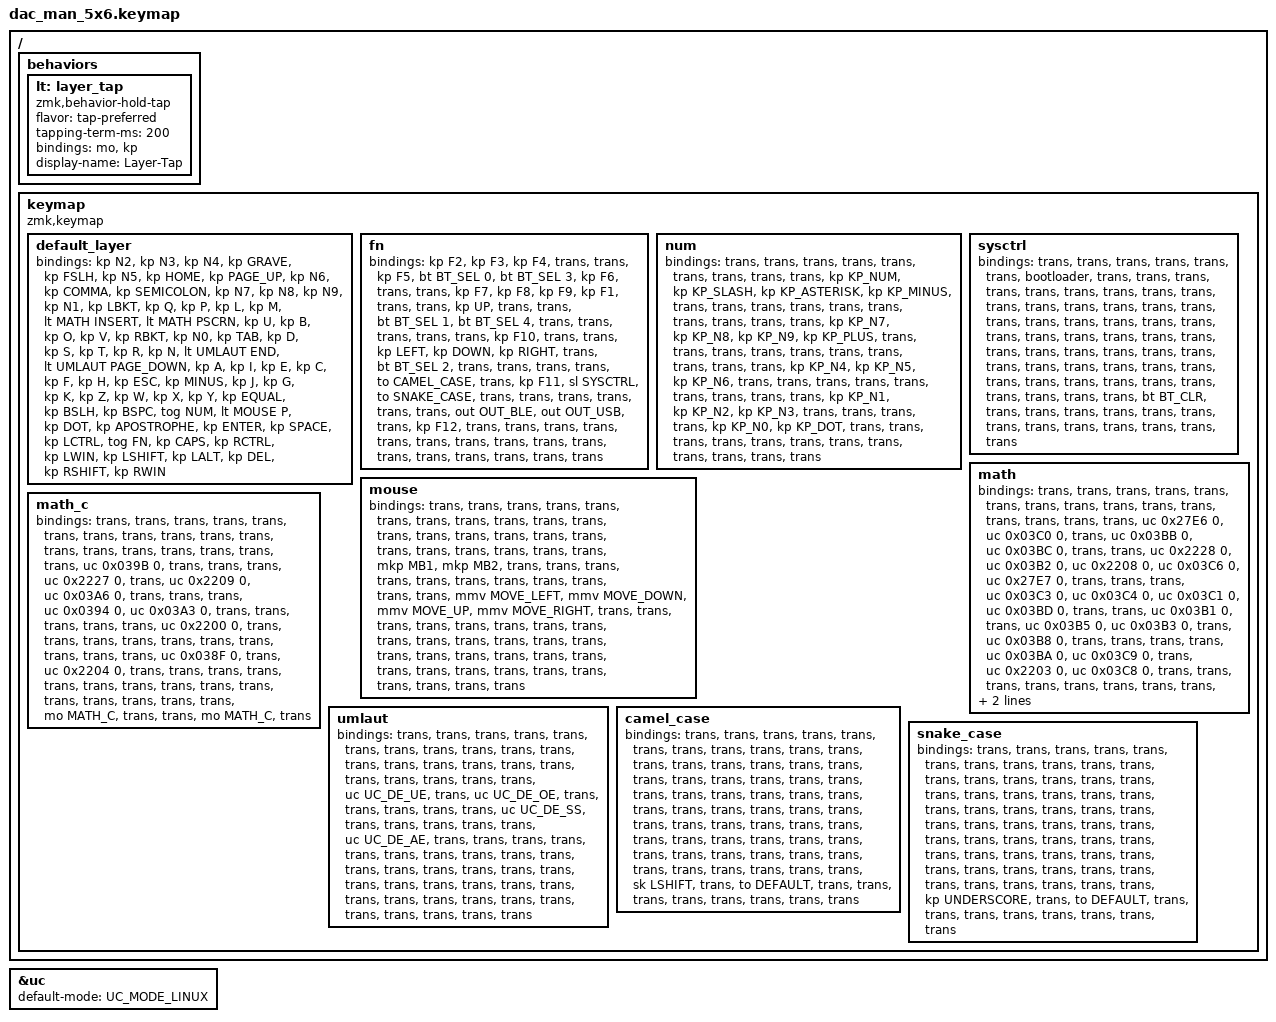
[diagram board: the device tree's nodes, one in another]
#include <behaviors.dtsi>
#include <dt-bindings/zmk/keys.h>
#include <dt-bindings/zmk/bt.h>
#include <dt-bindings/zmk/outputs.h>
#include <behaviors/unicode.dtsi>
#include <zmk-unicode/keys-extra.h>  // All glyphs except CJK
/* #include <zmk-unicode/keys-full.h>   // All glyphs including CJK */

// #define ZMK_POINTING_DEFAULT_MOVE_VAL 1500  // default: 600
// #define ZMK_POINTING_DEFAULT_SCRL_VAL 20    // default: 10

#include <dt-bindings/zmk/pointing.h>

#define DEFAULT     0
#define FN          1
#define NUM         2
#define SYSCTRL     3
#define MOUSE       4
#define MATH        5
#define MATH_C      6
#define UMLAUT      7
#define CAMEL_CASE  8
#define SNAKE_CASE  9

#define INDEX_RCTRL 63
#define INDEX_LSHIFT 65
#define INDEX_LALT 66

#define TAP_MS 10
#define WAIT_MS 10
#define TIMEOUT_MS 120

// QWERTY ///////////////

// #define INDEX_U 23
// #define INDEX_O 25
// #define INDEX_S 31
// #define INDEX_A 29

// QWERTY ///////////////

// // COLEMAK-DH ///////////
// #define INDEX_U 24
// #define INDEX_O 40
// #define INDEX_S 31
// #define INDEX_A 29
// // COLEMAK-DH ///////////

// carpalx: outputs-everythin_colemakstart //////////////////////////////////////////////////////////////////////////////////////////////////////////////////////////////////////////////////////////////////////////////////////////////////////////////
#define INDEX_BRACK_L 15
#define INDEX_Q 16
#define INDEX_P 17
#define INDEX_L 18
#define INDEX_M 19
#define INDEX_U 22
#define INDEX_B 23
#define INDEX_O 24
#define INDEX_V 25
#define INDEX_BRACK_R 26
#define INDEX_D 29
#define INDEX_S 30
#define INDEX_T 31
#define INDEX_R 32
#define INDEX_N 33
#define INDEX_A 36
#define INDEX_I 37
#define INDEX_E 38
#define INDEX_C 39
#define INDEX_F 40
#define INDEX_H 41
#define INDEX_J 44
#define INDEX_G 45
#define INDEX_K 46
#define INDEX_Z 47
#define INDEX_W 48
#define INDEX_X 49
#define INDEX_Y 50
// carpalx: outputs-everythin_colemakstart //////////////////////////////////////////////////////////////////////////////////////////////////////////////////////////////////////////////////////////////////////////////////////////////////////////////

&uc {
    default-mode = <UC_MODE_LINUX>;
};

/ {

    behaviors {
        lt: layer_tap {
            compatible = "zmk,behavior-hold-tap";
            #binding-cells = <2>;
            flavor = "tap-preferred";
            tapping-term-ms = <200>;
            bindings = <&mo>, <&kp>;
            display-name = "Layer-Tap";
        };
    };
    
    keymap {
        compatible = "zmk,keymap";

// // QWERTY //////////////////////////////////////////////////////////////////////////////////////////////////////////////////////////////////////////////////////////////////////////////////////////////////////////////////
//         default_layer {
//             bindings = <
// &kp GRAVE   &kp N2     &kp N3    &kp N4     &kp N5     &kp N6       &kp HOME                            &kp PSCRN       &kp N7     &kp N8     &kp N9     &kp N0     &kp MINUS      &kp EQUAL
// &kp N1      &kp Q      &kp W     &kp E      &kp R      &kp T        &kp INSERT                          &kp PAGE_UP     &kp Y      &kp U      &kp I      &kp O      &kp P          &kp BSLH
// &kp TAB     &kp A      &kp S     &kp D      &kp F      &kp G        &kp END                             &kp PAGE_DOWN   &kp H      &kp J      &kp K      &kp L      &kp SEMICOLON  &kp APOSTROPHE
// &kp ESC     &kp Z      &kp X     &kp C      &kp V      &kp B                                                            &kp N      &kp M      &kp COMMA  &kp DOT    &kp FSLH       &kp BSPC
//                        &tog NUM  &kp P                                                                                                        &kp LBKT   &kp RBKT
//                                             &kp ENTER    &kp SPACE   &kp LCTRL                          &tog FN &kp CAPS        &kp RCTRL
//                                             &kp LWIN     &kp LSHIFT  &kp LALT                           &kp DEL &kp RSHIFT      &kp RWIN
//             >;
//         };
// // QWERTY //////////////////////////////////////////////////////////////////////////////////////////////////////////////////////////////////////////////////////////////////////////////////////////////////////////////////

// // COLEMAK-DH //////////////////////////////////////////////////////////////////////////////////////////////////////////////////////////////////////////////////////////////////////////////////////////////////////////////
//         default_layer {
//             bindings = <
// &kp GRAVE   &kp N2     &kp N3    &kp N4     &kp N5     &kp N6       &kp HOME                            &kp PAGE_UP     &kp N7     &kp N8     &kp N9     &kp N0     &kp MINUS      &kp EQUAL
// &kp N1      &kp Q      &kp W     &kp F      &kp P      &kp B        &kp INSERT                          &kp PSCRN       &kp J      &kp L      &kp U      &kp Y      &kp SEMICOLON  &kp BSLH
// &kp TAB     &kp A      &kp R     &kp S      &kp T      &kp G        &kp END                             &kp PAGE_DOWN   &kp M      &kp N      &kp E      &kp I      &kp O          &kp APOSTROPHE
// &kp ESC     &kp Z      &kp X     &kp C      &kp D      &kp V                                                            &kp K      &kp H      &kp COMMA  &kp DOT    &kp FSLH       &kp BSPC
//                        &tog NUM  &kp P                                                                                                        &kp LBKT   &kp RBKT
//                                             &lt COLEMAK_ARROWS ENTER  &kp SPACE    &kp LCTRL                           &tog FN         &kp CAPS   &kp RCTRL
//                                             &kp LWIN   &kp LSHIFT   &kp LALT                            &kp DEL         &kp RSHIFT &kp RWIN
//             >;
//         };
// // COLEMAK-DH //////////////////////////////////////////////////////////////////////////////////////////////////////////////////////////////////////////////////////////////////////////////////////////////////////////////

// carpalx: outputs-everythin_colemakstart //////////////////////////////////////////////////////////////////////////////////////////////////////////////////////////////////////////////////////////////////////////////////////////////////////////////
        default_layer {
            bindings = <
&kp N2  &kp N3      &kp N4      &kp GRAVE   &kp FSLH    &kp N5      &kp HOME                                &kp PAGE_UP             &kp N6      &kp COMMA   &kp SEMICOLON   &kp N7      &kp N8      &kp N9
&kp N1  &kp LBKT    &kp Q       &kp P       &kp L       &kp M       &lt MATH INSERT                         &lt MATH PSCRN          &kp U       &kp B       &kp O           &kp V       &kp RBKT    &kp N0
&kp TAB &kp D       &kp S       &kp T       &kp R       &kp N       &lt UMLAUT END                          &lt UMLAUT PAGE_DOWN    &kp A       &kp I       &kp E           &kp C       &kp F       &kp H    
&kp ESC &kp MINUS   &kp J       &kp G       &kp K       &kp Z                                                                       &kp W       &kp X       &kp Y           &kp EQUAL   &kp BSLH    &kp BSPC
                    &tog NUM    &lt MOUSE P                                                                                                                 &kp DOT         &kp APOSTROPHE
                                            &kp ENTER   &kp SPACE   &kp LCTRL                               &tog FN                 &kp CAPS    &kp RCTRL
                                            &kp LWIN    &kp LSHIFT  &kp LALT                                &kp DEL                 &kp RSHIFT  &kp RWIN
            >;
        };
// carpalx: outputs-everythin_colemakstart //////////////////////////////////////////////////////////////////////////////////////////////////////////////////////////////////////////////////////////////////////////////////////////////////////////////

        fn{
            bindings = <
&kp F2          &kp F3          &kp F4      &trans          &trans      &kp F5  &bt BT_SEL 0                                    &bt BT_SEL 3  &kp F6    &trans    &trans          &kp F7         &kp F8  &kp F9
&kp F1          &trans          &trans      &kp UP          &trans      &trans  &bt BT_SEL 1                                    &bt BT_SEL 4  &trans    &trans    &trans          &trans         &trans  &kp F10
&trans          &trans          &kp LEFT    &kp DOWN        &kp RIGHT   &trans  &bt BT_SEL 2                                    &trans        &trans    &trans    &trans          &to CAMEL_CASE &trans  &kp F11
&sl SYSCTRL     &to SNAKE_CASE  &trans      &trans          &trans      &trans                                                                &trans    &trans    &out OUT_BLE    &out OUT_USB   &trans  &kp F12
                                &trans      &trans                                                                                                      &trans          &trans
                                                            &trans      &trans  &trans                                          &trans        &trans    &trans
                                                            &trans      &trans  &trans                                          &trans        &trans    &trans
            >;
        };

        num{
            bindings = <
&trans  &trans  &trans  &trans  &trans  &trans  &trans                      &trans  &trans  &kp KP_NUM  &kp KP_SLASH  &kp KP_ASTERISK    &kp KP_MINUS    &trans
&trans  &trans  &trans  &trans  &trans  &trans  &trans                      &trans  &trans  &kp KP_N7   &kp KP_N8     &kp KP_N9          &kp KP_PLUS     &trans
&trans  &trans  &trans  &trans  &trans  &trans  &trans                      &trans  &trans  &kp KP_N4   &kp KP_N5     &kp KP_N6          &trans          &trans
&trans  &trans  &trans  &trans  &trans  &trans                                      &trans  &kp KP_N1   &kp KP_N2     &kp KP_N3          &trans          &trans
        &trans  &trans                                                                                  &kp KP_N0     &kp KP_DOT
                                &trans  &trans  &trans                      &trans  &trans  &trans
                                &trans  &trans  &trans                      &trans  &trans  &trans
            >;
        };

        sysctrl{
            bindings = <
&trans  &trans  &trans  &trans  &trans  &trans  &bootloader                 &trans  &trans  &trans      &trans  &trans  &trans  &trans
&trans  &trans  &trans  &trans  &trans  &trans  &trans                      &trans  &trans  &trans      &trans  &trans  &trans  &trans
&trans  &trans  &trans  &trans  &trans  &trans  &trans                      &trans  &trans  &trans      &trans  &trans  &trans  &trans
&trans  &trans  &trans  &trans  &trans  &trans                                      &trans  &trans      &trans  &trans  &trans  &trans
                        &trans  &trans                                                      &bt BT_CLR  &trans
                                        &trans  &trans  &trans      &trans  &trans  &trans
                                        &trans  &trans  &trans      &trans  &trans  &trans
            >;
        };

        mouse{
            bindings = <
&trans  &trans  &trans  &trans  &trans  &trans  &trans       &trans  &trans         &trans          &trans          &trans          &trans  &trans
&trans  &trans  &trans  &trans  &trans  &trans  &trans       &trans  &trans         &mkp MB1        &mkp MB2        &trans          &trans  &trans
&trans  &trans  &trans  &trans  &trans  &trans  &trans       &trans  &mmv MOVE_LEFT &mmv MOVE_DOWN  &mmv MOVE_UP    &mmv MOVE_RIGHT &trans  &trans
&trans  &trans  &trans  &trans  &trans  &trans                       &trans         &trans          &trans          &trans          &trans  &trans
                &trans  &trans                                                                      &trans          &trans
                                &trans  &trans  &trans       &trans  &trans         &trans
                                &trans  &trans  &trans       &trans  &trans         &trans
            >;
        };


        math{
            bindings = <
&trans  &trans          &trans          &trans          &trans          &trans          &trans                  &trans  &trans          &trans          &trans          &trans          &trans          &trans
&trans  &uc 0x27E6 0    &uc 0x03C0 0    &trans          &uc 0x03BB 0    &uc 0x03BC 0    &trans                  &trans  &uc 0x2228 0    &uc 0x03B2 0    &uc 0x2208 0    &uc 0x03C6 0    &uc 0x27E7 0    &trans
&trans  &trans          &uc 0x03C3 0    &uc 0x03C4 0    &uc 0x03C1 0    &uc 0x03BD 0    &trans                  &trans  &uc 0x03B1 0    &trans          &uc 0x03B5 0    &uc 0x03B3 0    &trans          &uc 0x03B8 0
&trans  &trans          &trans          &trans          &uc 0x03BA 0    &uc 0x03C9 0                                    &trans          &uc 0x2203 0    &uc 0x03C8 0    &trans          &trans          &trans
                        &trans          &trans                                                                                                          &trans          &trans
                                                        &trans          &trans          &trans                  &trans  &trans          &trans
                                                        &trans          &lt MATH_C      &trans                  &trans  &trans          &trans
            >;
        };

        math_c{
            bindings = <
&trans  &trans              &trans          &trans          &trans          &trans          &trans                  &trans  &trans              &trans          &trans          &trans          &trans  &trans
&trans  &trans              &trans          &trans          &uc 0x039B 0    &trans          &trans                  &trans  &uc 0x2227 0        &trans          &uc 0x2209 0    &uc 0x03A6 0    &trans  &trans
&trans  &uc 0x0394 0        &uc 0x03A3 0    &trans          &trans          &trans          &trans                  &trans  &uc 0x2200 0        &trans          &trans          &trans          &trans  &trans
&trans  &trans              &trans          &trans          &trans          &uc 0x038F 0                                    &trans              &uc 0x2204 0    &trans          &trans          &trans  &trans
                            &trans          &trans                                                                                                              &trans          &trans
                                                            &trans          &trans          &trans                  &trans  &trans              &trans
                                                            &trans          &mo MATH_C      &trans                  &trans  &mo MATH_C          &trans
            >;
        };

        umlaut{
            bindings = <
&trans  &trans  &trans          &trans  &trans  &trans  &trans              &trans  &trans          &trans  &trans          &trans  &trans  &trans
&trans  &trans  &trans          &trans  &trans  &trans  &trans              &trans  &uc UC_DE_UE    &trans  &uc UC_DE_OE    &trans  &trans  &trans
&trans  &trans  &uc UC_DE_SS    &trans  &trans  &trans  &trans              &trans  &uc UC_DE_AE    &trans  &trans          &trans  &trans  &trans
&trans  &trans  &trans          &trans  &trans  &trans                              &trans          &trans  &trans          &trans  &trans  &trans
                &trans          &trans                                                                      &trans          &trans
                                        &trans  &trans  &trans              &trans  &trans          &trans
                                        &trans  &trans  &trans              &trans  &trans          &trans
            >;
        };

         camel_case{
             bindings = <
 &trans  &trans  &trans  &trans  &trans  &trans     &trans      &trans      &trans  &trans  &trans  &trans  &trans  &trans
 &trans  &trans  &trans  &trans  &trans  &trans     &trans      &trans      &trans  &trans  &trans  &trans  &trans  &trans
 &trans  &trans  &trans  &trans  &trans  &trans     &trans      &trans      &trans  &trans  &trans  &trans  &trans  &trans
 &trans  &trans  &trans  &trans  &trans  &trans                             &trans  &trans  &trans  &trans  &trans  &trans
                 &trans  &trans                                                     &trans  &trans
                                 &trans  &sk LSHIFT &trans      &to DEFAULT  &trans &trans
                                 &trans  &trans     &trans      &trans      &trans  &trans
             >;
         };

         snake_case{
             bindings = <
 &trans  &trans  &trans  &trans  &trans  &trans         &trans          &trans      &trans  &trans  &trans  &trans  &trans  &trans
 &trans  &trans  &trans  &trans  &trans  &trans         &trans          &trans      &trans  &trans  &trans  &trans  &trans  &trans
 &trans  &trans  &trans  &trans  &trans  &trans         &trans          &trans      &trans  &trans  &trans  &trans  &trans  &trans
 &trans  &trans  &trans  &trans  &trans  &trans                                     &trans  &trans  &trans  &trans  &trans  &trans
                 &trans  &trans                                                                     &trans  &trans
                                 &trans  &kp UNDERSCORE &trans          &to DEFAULT &trans  &trans
                                 &trans  &trans         &trans          &trans      &trans  &trans
             >;
         };

//         FN{
//             bindings = <
// &trans  &trans  &trans  &trans  &trans  &trans  &trans       &trans  &trans  &trans  &trans  &trans  &trans  &trans
// &trans  &trans  &trans  &trans  &trans  &trans  &trans       &trans  &trans  &trans  &trans  &trans  &trans  &trans
// &trans  &trans  &trans  &trans  &trans  &trans  &trans       &trans  &trans  &trans  &trans  &trans  &trans  &trans
// &trans  &trans  &trans  &trans  &trans  &trans                       &trans  &trans  &trans  &trans  &trans  &trans
//                 &trans  &trans                                                       &trans  &trans
//                                 &trans  &trans  &trans       &trans  &trans  &trans
//                                 &trans  &trans  &trans       &trans  &trans  &trans
//             >;
//         };



   };
};
